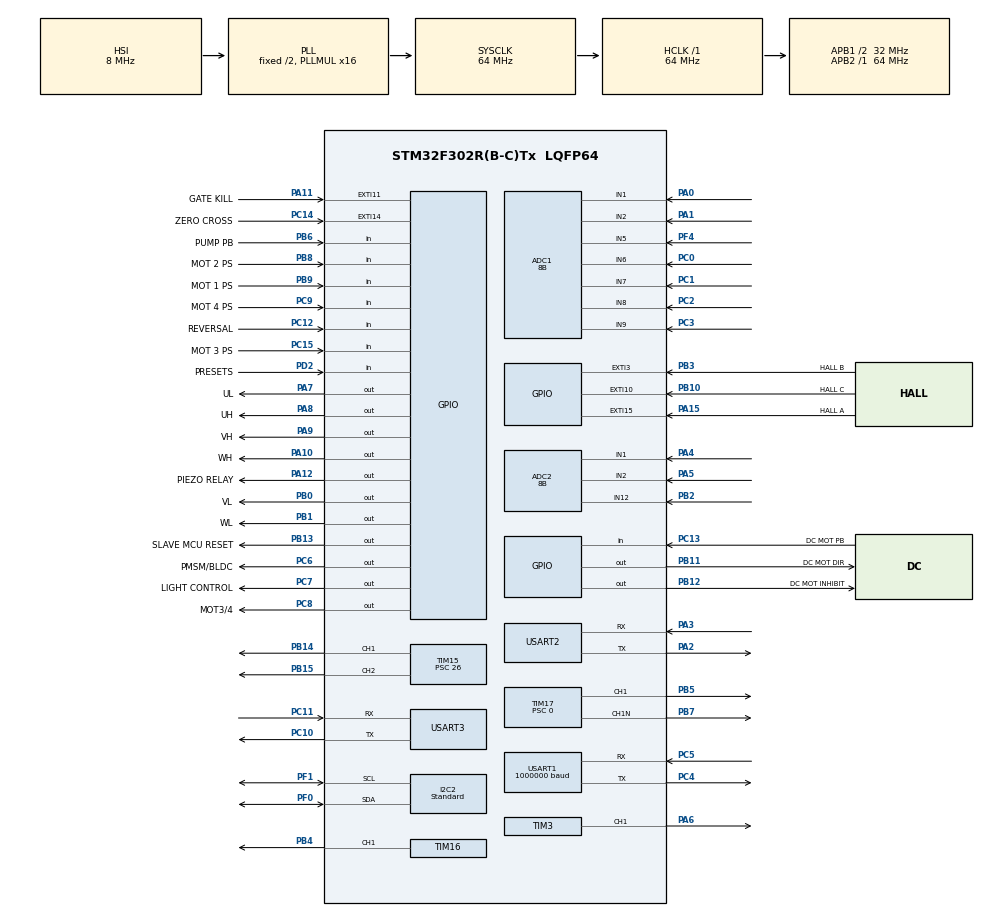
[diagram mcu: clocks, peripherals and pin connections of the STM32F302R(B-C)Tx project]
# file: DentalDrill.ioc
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ADC1.Channel-0\#ChannelRegularConversion=ADC_CHANNEL_1
ADC1.ClockPrescaler=ADC_CLOCK_ASYNC_DIV1
ADC1.ContinuousConvMode=DISABLE
ADC1.DMAContinuousRequests=DISABLE
ADC1.DataAlign=ADC_DATAALIGN_RIGHT
ADC1.DiscontinuousConvMode=DISABLE
ADC1.EOCSelection=ADC_EOC_SINGLE_CONV
ADC1.EnableAnalogWatchDog1=false
ADC1.EnableAnalogWatchDog2=false
ADC1.EnableAnalogWatchDog3=false
ADC1.EnableInjectedConversion=ENABLE
ADC1.EnableRegularConversion=ENABLE
ADC1.ExternalTrigConv=ADC_SOFTWARE_START
ADC1.ExternalTrigConvEdge=ADC_EXTERNALTRIGCONVEDGE_NONE
ADC1.InjNumberOfConversion=0
ADC1.LowPowerAutoWait=DISABLE
ADC1.NbrOfConversion=1
ADC1.NbrOfConversionFlag=1
ADC1.Offset-0\#ChannelRegularConversion=0
ADC1.OffsetNumber-0\#ChannelRegularConversion=ADC_OFFSET_NONE
ADC1.Overrun=ADC_OVR_DATA_OVERWRITTEN
ADC1.Rank-0\#ChannelRegularConversion=1
ADC1.Resolution=ADC_RESOLUTION_8B
ADC1.SamplingTime-0\#ChannelRegularConversion=ADC_SAMPLETIME_1CYCLE_5
ADC1.ScanConvMode=ADC_SCAN_DISABLE
ADC1.SubFamily=STM32F302xC
ADC1.master=1
ADC2.Channel-0\#ChannelRegularConversion=ADC_CHANNEL_12
ADC2.NbrOfConversionFlag=1
ADC2.Offset-0\#ChannelRegularConversion=0
ADC2.OffsetNumber-0\#ChannelRegularConversion=ADC_OFFSET_NONE
ADC2.Rank-0\#ChannelRegularConversion=1
ADC2.Resolution=ADC_RESOLUTION_8B
ADC2.SamplingTime-0\#ChannelRegularConversion=ADC_SAMPLETIME_1CYCLE_5
ADC2.SubFamily=STM32F302xC
I2C2.I2C_Speed_Mode=I2C_Standard
I2C2.Timing=0x10707DBC
Mcu.Family=STM32F3
Mcu.Name=STM32F302R(B-C)Tx
Mcu.Package=LQFP64
NVIC.EXTI15_10_IRQn=true\:5\:0\:true\:false\:true\:true
NVIC.EXTI3_IRQn=true\:5\:0\:true\:false\:true\:true
NVIC.PriorityGroup=NVIC_PRIORITYGROUP_4
NVIC.RCC_IRQn=true\:5\:0\:true\:false\:true\:true
NVIC.TIM1_UP_TIM16_IRQn=true\:5\:0\:true\:false\:true\:false
NVIC.TIM2_IRQn=true\:5\:0\:true\:false\:true\:true
NVIC.TIM4_IRQn=true\:5\:0\:true\:false\:true\:false
NVIC.TimeBase=TIM4_IRQn
NVIC.TimeBaseIP=TIM4
NVIC.USART1_IRQn=true\:5\:0\:true\:false\:true\:true
NVIC.USART2_IRQn=true\:5\:0\:true\:false\:true\:true
NVIC.USART3_IRQn=true\:5\:0\:true\:false\:true\:true
PA0.Mode=IN1-Single-Ended
PA0.Signal=ADC1_IN1
PA1.Mode=IN2-Single-Ended
PA1.Signal=ADC1_IN2
PA10.GPIO_Label=WH
PA10.GPIO_ModeDefaultOutputPP=GPIO_MODE_OUTPUT_PP
PA10.GPIO_PuPd=GPIO_PULLDOWN
PA10.PinState=GPIO_PIN_RESET
PA10.Signal=GPIO_Output
PA11.GPIO_Label=GATE KILL
PA11.GPIO_ModeDefaultEXTI=GPIO_MODE_IT_FALLING
PA11.GPIO_PuPd=GPIO_PULLUP
PA11.Signal=GPXTI11
PA12.GPIO_Label=PIEZO RELAY
PA12.GPIO_ModeDefaultOutputPP=GPIO_MODE_OUTPUT_PP
PA12.GPIO_PuPd=GPIO_PULLDOWN
PA12.PinState=GPIO_PIN_RESET
PA12.Signal=GPIO_Output
PA13.Mode=Serial_Wire
PA13.Signal=SYS_JTMS-SWDIO
PA14.Mode=Serial_Wire
PA14.Signal=SYS_JTCK-SWCLK
PA15.GPIO_Label=HALL A
PA15.GPIO_ModeDefaultEXTI=GPIO_MODE_IT_RISING_FALLING
PA15.GPIO_PuPd=GPIO_PULLUP
PA15.Signal=GPXTI15
PA2.Mode=Asynchronous
PA2.Signal=USART2_TX
PA3.Mode=Asynchronous
PA3.Signal=USART2_RX
PA4.Mode=IN1-Single-Ended
PA4.Signal=ADC2_IN1
PA5.Mode=IN2-Single-Ended
PA5.Signal=ADC2_IN2
PA6.Signal=S_TIM3_CH1
PA7.GPIO_Label=UL
PA7.GPIO_ModeDefaultOutputPP=GPIO_MODE_OUTPUT_PP
PA7.GPIO_PuPd=GPIO_PULLDOWN
PA7.PinState=GPIO_PIN_RESET
PA7.Signal=GPIO_Output
PA8.GPIO_Label=UH
PA8.GPIO_ModeDefaultOutputPP=GPIO_MODE_OUTPUT_PP
PA8.GPIO_PuPd=GPIO_PULLDOWN
PA8.PinState=GPIO_PIN_RESET
PA8.Signal=GPIO_Output
PA9.GPIO_Label=VH
PA9.GPIO_ModeDefaultOutputPP=GPIO_MODE_OUTPUT_PP
PA9.GPIO_PuPd=GPIO_PULLDOWN
PA9.PinState=GPIO_PIN_RESET
PA9.Signal=GPIO_Output
PB0.GPIO_Label=VL
PB0.GPIO_ModeDefaultOutputPP=GPIO_MODE_OUTPUT_PP
PB0.GPIO_PuPd=GPIO_PULLDOWN
PB0.PinState=GPIO_PIN_RESET
PB0.Signal=GPIO_Output
PB1.GPIO_Label=WL
PB1.GPIO_ModeDefaultOutputPP=GPIO_MODE_OUTPUT_PP
PB1.GPIO_PuPd=GPIO_PULLDOWN
PB1.PinState=GPIO_PIN_RESET
PB1.Signal=GPIO_Output
PB10.GPIO_Label=HALL C
PB10.GPIO_ModeDefaultEXTI=GPIO_MODE_IT_RISING_FALLING
PB10.GPIO_PuPd=GPIO_PULLUP
PB10.Signal=GPXTI10
PB11.GPIO_Label=DC MOT DIR
PB11.GPIO_ModeDefaultOutputPP=GPIO_MODE_OUTPUT_PP
PB11.GPIO_PuPd=GPIO_PULLDOWN
PB11.PinState=GPIO_PIN_RESET
PB11.Signal=GPIO_Output
PB12.GPIO_Label=DC MOT INHIBIT
PB12.GPIO_ModeDefaultOutputPP=GPIO_MODE_OUTPUT_OD
PB12.GPIO_PuPd=GPIO_PULLUP
PB12.PinState=GPIO_PIN_SET
PB12.Signal=GPIO_Output
PB13.GPIO_Label=SLAVE MCU RESET
PB13.GPIO_ModeDefaultOutputPP=GPIO_MODE_OUTPUT_PP
PB13.GPIO_PuPd=GPIO_PULLUP
PB13.PinState=GPIO_PIN_SET
PB13.Signal=GPIO_Output
PB14.Signal=S_TIM15_CH1
PB15.Signal=S_TIM15_CH2
PB2.Mode=IN12-Single-Ended
PB2.Signal=ADC2_IN12
PB3.GPIO_Label=HALL B
PB3.GPIO_ModeDefaultEXTI=GPIO_MODE_IT_RISING_FALLING
PB3.GPIO_PuPd=GPIO_PULLUP
PB3.Signal=GPXTI3
PB4.Signal=S_TIM16_CH1
PB5.Signal=S_TIM17_CH1
PB6.GPIO_Label=PUMP PB
PB6.GPIO_Mode=GPIO_MODE_INPUT
PB6.GPIO_PuPd=GPIO_PULLUP
PB6.Signal=GPIO_Input
PB7.Mode=PWM Generation1 CH1 CH1N
PB7.Signal=TIM17_CH1N
PB8.GPIO_Label=MOT 2 PS
PB8.GPIO_Mode=GPIO_MODE_INPUT
PB8.GPIO_PuPd=GPIO_PULLDOWN
PB8.Signal=GPIO_Input
PB9.GPIO_Label=MOT 1 PS
PB9.GPIO_Mode=GPIO_MODE_INPUT
PB9.GPIO_PuPd=GPIO_PULLDOWN
PB9.Signal=GPIO_Input
PC0.Signal=ADCx_IN6
PC1.Signal=ADCx_IN7
PC10.Mode=Asynchronous
PC10.Signal=USART3_TX
PC11.Mode=Asynchronous
PC11.Signal=USART3_RX
PC12.GPIO_Label=REVERSAL
PC12.GPIO_Mode=GPIO_MODE_INPUT
PC12.GPIO_PuPd=GPIO_PULLUP
PC12.Signal=GPIO_Input
PC13.GPIO_Label=DC MOT PB
PC13.GPIO_PuPd=GPIO_PULLUP
PC13.Signal=GPIO_Input
PC14-OSC32_IN.GPIO_Label=ZERO CROSS
PC14-OSC32_IN.GPIO_PuPd=GPIO_PULLUP
PC14-OSC32_IN.Signal=GPXTI14
PC15-OSC32_OUT.GPIO_Label=MOT 3 PS
PC15-OSC32_OUT.GPIO_PuPd=GPIO_PULLDOWN
PC15-OSC32_OUT.Signal=GPIO_Input
PC2.Signal=ADCx_IN8
PC3.Signal=ADCx_IN9
PC4.Mode=Asynchronous
PC4.Signal=USART1_TX
PC5.Mode=Asynchronous
PC5.Signal=USART1_RX
PC6.GPIO_Label=PMSM/BLDC
PC6.GPIO_ModeDefaultOutputPP=GPIO_MODE_OUTPUT_PP
PC6.GPIO_PuPd=GPIO_PULLDOWN
PC6.PinState=GPIO_PIN_RESET
PC6.Signal=GPIO_Output
PC7.GPIO_Label=LIGHT CONTROL
PC7.GPIO_PuPd=GPIO_PULLDOWN
PC7.Signal=GPIO_Output
PC8.GPIO_Label=MOT3/4
PC8.GPIO_ModeDefaultOutputPP=GPIO_MODE_OUTPUT_PP
PC8.GPIO_PuPd=GPIO_PULLDOWN
PC8.PinState=GPIO_PIN_RESET
PC8.Signal=GPIO_Output
PC9.GPIO_Label=MOT 4 PS
PC9.GPIO_Mode=GPIO_MODE_INPUT
PC9.GPIO_PuPd=GPIO_PULLDOWN
PC9.Signal=GPIO_Input
PD2.GPIO_Label=PRESETS
PD2.GPIO_Mode=GPIO_MODE_INPUT
PD2.GPIO_PuPd=GPIO_PULLUP
PD2.Signal=GPIO_Input
PF0-OSC_IN.Mode=I2C
PF0-OSC_IN.Signal=I2C2_SDA
PF1-OSC_OUT.Mode=I2C
PF1-OSC_OUT.Signal=I2C2_SCL
PF4.Mode=IN5-Single-Ended
PF4.Signal=ADC1_IN5
ProjectManager.HeapSize=0x200
ProjectManager.StackSize=0x400
ProjectManager.TargetToolchain=Makefile
RCC.AHBFreq_Value=64000000
RCC.APB1CLKDivider=RCC_HCLK_DIV2
RCC.APB1Freq_Value=32000000
RCC.APB1TimFreq_Value=64000000
RCC.APB2Freq_Value=64000000
RCC.APB2TimFreq_Value=64000000
RCC.CortexFreq_Value=64000000
RCC.HCLKFreq_Value=64000000
RCC.HSE_VALUE=8000000
RCC.HSI_VALUE=8000000
RCC.I2c2ClockSelection=RCC_I2C2CLKSOURCE_SYSCLK
RCC.LSE_VALUE=32768
RCC.PLLMUL=RCC_PLL_MUL16
RCC.SYSCLKFreq_VALUE=64000000
RCC.SYSCLKSourceVirtual=RCC_SYSCLKSOURCE_PLLCLK
RCC.USBFreq_Value=64000000
SH.ADCx_IN6.0=ADC1_IN6,IN6-Single-Ended
SH.ADCx_IN7.0=ADC1_IN7,IN7-Single-Ended
SH.ADCx_IN8.0=ADC1_IN8,IN8-Single-Ended
SH.ADCx_IN9.0=ADC1_IN9,IN9-Single-Ended
SH.S_TIM15_CH1.0=TIM15_CH1,PWM Generation1 CH1
SH.S_TIM15_CH2.0=TIM15_CH2,PWM Generation2 CH2
SH.S_TIM16_CH1.0=TIM16_CH1,PWM Generation1 CH1
SH.S_TIM17_CH1.0=TIM17_CH1,PWM Generation1 CH1 CH1N
SH.S_TIM3_CH1.0=TIM3_CH1,PWM Generation1 CH1
TIM15.Channel-PWM\ Generation1\ CH1=TIM_CHANNEL_1
TIM15.Channel-PWM\ Generation2\ CH2=TIM_CHANNEL_2
TIM15.Period=99
TIM15.Prescaler=26
TIM15.Pulse-PWM\ Generation1\ CH1=50
TIM15.Pulse-PWM\ Generation2\ CH2=50
TIM16.Channel=TIM_CHANNEL_1
TIM16.Period=99
TIM16.Prescaler=26
TIM16.Pulse=50
TIM17.Channel=TIM_CHANNEL_1
TIM17.DeadTime=18
TIM17.Period=639
TIM17.Prescaler=0
TIM17.Pulse=360
TIM2.AutoReloadPreload=TIM_AUTORELOAD_PRELOAD_DISABLE
TIM2.ClockDivision=TIM_CLOCKDIVISION_DIV1
TIM2.Period=0xFFFFFFFF
TIM2.Prescaler=63
TIM2.TIM_MasterOutputTrigger=TIM_TRGO_RESET
TIM3.Channel-PWM\ Generation1\ CH1=TIM_CHANNEL_1
TIM3.Period=99
TIM3.Prescaler=639
TIM3.Pulse-PWM\ Generation1\ CH1=50
USART1.BaudRate=1000000
USART1.VirtualMode-Asynchronous=VM_ASYNC
USART2.VirtualMode-Asynchronous=VM_ASYNC
USART3.VirtualMode-Asynchronous=VM_ASYNC
VP_SYS_VS_tim4.Mode=TIM4
VP_TIM15_VS_ClockSourceINT.Mode=Internal
VP_TIM16_VS_ClockSourceINT.Mode=Enable_Timer
VP_TIM17_VS_ClockSourceINT.Mode=Enable_Timer
VP_TIM2_VS_ClockSourceINT.Mode=Internal
VP_TIM3_VS_ClockSourceINT.Mode=Internal
board=DentalDrill

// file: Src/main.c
/**
  ******************************************************************************
  * @file           : main.c
  * @brief          : Main program body
  ******************************************************************************
  ** This notice applies to any and all portions of this file
  * that are not between comment pairs USER CODE BEGIN and
  * USER CODE END. Other portions of this file, whether
  * inserted by the user or by software development tools
  * are owned by their respective copyright owners.
  *
  * COPYRIGHT(c) 2018 STMicroelectronics
  *
  * Redistribution and use in source and binary forms, with or without modification,
  * are permitted provided that the following conditions are met:
  *   1. Redistributions of source code must retain the above copyright notice,
  *      this list of conditions and the following disclaimer.
  *   2. Redistributions in binary form must reproduce the above copyright notice,
  *      this list of conditions and the following disclaimer in the documentation
  *      and/or other materials provided with the distribution.
  *   3. Neither the name of STMicroelectronics nor the names of its contributors
  *      may be used to endorse or promote products derived from this software
  *      without specific prior written permission.
  *
  * THIS SOFTWARE IS PROVIDED BY THE COPYRIGHT HOLDERS AND CONTRIBUTORS "AS IS"
  * AND ANY EXPRESS OR IMPLIED WARRANTIES, INCLUDING, BUT NOT LIMITED TO, THE
  * IMPLIED WARRANTIES OF MERCHANTABILITY AND FITNESS FOR A PARTICULAR PURPOSE ARE
  * DISCLAIMED. IN NO EVENT SHALL THE COPYRIGHT HOLDER OR CONTRIBUTORS BE LIABLE
  * FOR ANY DIRECT, INDIRECT, INCIDENTAL, SPECIAL, EXEMPLARY, OR CONSEQUENTIAL
  * DAMAGES (INCLUDING, BUT NOT LIMITED TO, PROCUREMENT OF SUBSTITUTE GOODS OR
  * SERVICES; LOSS OF USE, DATA, OR PROFITS; OR BUSINESS INTERRUPTION) HOWEVER
  * CAUSED AND ON ANY THEORY OF LIABILITY, WHETHER IN CONTRACT, STRICT LIABILITY,
  * OR TORT (INCLUDING NEGLIGENCE OR OTHERWISE) ARISING IN ANY WAY OUT OF THE USE
  * OF THIS SOFTWARE, EVEN IF ADVISED OF THE POSSIBILITY OF SUCH DAMAGE.
  *
  ******************************************************************************
  */
#include "main.h"
#include "stm32f3xx_hal.h"
#include "adc.h"
#include "i2c.h"
#include "tim.h"
#include "usart.h"
#include "gpio.h"

/* USER CODE BEGIN PV */
/* Private variables ---------------------------------------------------------*/

/* USER CODE END PV */

void SystemClock_Config(void);

/* USER CODE BEGIN PFP */
/* Private function prototypes -----------------------------------------------*/

/* USER CODE END PFP */

/* USER CODE BEGIN 0 */
//This is a somewhat dirty hack to remove the STM main function from the build while not affecting
//generated HAL code, aside from what is included in the main function. Driver initialization is now
//the responsibility of the application and jel (i.e. the MX_GPIO_Init(), MX_..._Init() functions).
//The HAL_Init() and SystemClock_Config() functions are handled by the jel on bootup, and the core
//timer, UART and GPIO are also initialized on startup.
__attribute__((unused)) static void DUMMY(void)
{
#ifdef false
/* USER CODE END 0 */

int main(void)
{

  /* MCU Configuration----------------------------------------------------------*/

  /* Reset of all peripherals, Initializes the Flash interface and the Systick. */
  HAL_Init();

  /* Configure the system clock */
  SystemClock_Config();

  /* Initialize all configured peripherals */
  MX_GPIO_Init();
  MX_USART2_UART_Init();
  MX_USART1_UART_Init();
  MX_TIM17_Init();
  MX_TIM16_Init();
  MX_TIM3_Init();
  MX_TIM15_Init();
  MX_ADC1_Init();
  MX_ADC2_Init();
  MX_I2C2_Init();
  MX_USART3_UART_Init();
  MX_TIM2_Init();

  /* Infinite loop */
  while (1)
  {

  /* USER CODE BEGIN 3 */

  }
#endif
  /* USER CODE END 3 */

}

void SystemClock_Config(void)
{

  RCC_OscInitTypeDef RCC_OscInitStruct;
  RCC_ClkInitTypeDef RCC_ClkInitStruct;
  RCC_PeriphCLKInitTypeDef PeriphClkInit;

    /**Initializes the CPU, AHB and APB busses clocks
    */
  RCC_OscInitStruct.OscillatorType = RCC_OSCILLATORTYPE_HSI;
  RCC_OscInitStruct.HSIState = RCC_HSI_ON;
  RCC_OscInitStruct.HSICalibrationValue = 16;
  RCC_OscInitStruct.PLL.PLLState = RCC_PLL_ON;
  RCC_OscInitStruct.PLL.PLLSource = RCC_PLLSOURCE_HSI;
  RCC_OscInitStruct.PLL.PLLMUL = RCC_PLL_MUL16;
  if (HAL_RCC_OscConfig(&RCC_OscInitStruct) != HAL_OK)
  {
    _Error_Handler(__FILE__, __LINE__);
  }

    /**Initializes the CPU, AHB and APB busses clocks
    */
  RCC_ClkInitStruct.ClockType = RCC_CLOCKTYPE_HCLK|RCC_CLOCKTYPE_SYSCLK
                              |RCC_CLOCKTYPE_PCLK1|RCC_CLOCKTYPE_PCLK2;
  RCC_ClkInitStruct.SYSCLKSource = RCC_SYSCLKSOURCE_PLLCLK;
  RCC_ClkInitStruct.AHBCLKDivider = RCC_SYSCLK_DIV1;
  RCC_ClkInitStruct.APB1CLKDivider = RCC_HCLK_DIV2;
  RCC_ClkInitStruct.APB2CLKDivider = RCC_HCLK_DIV1;

  if (HAL_RCC_ClockConfig(&RCC_ClkInitStruct, FLASH_LATENCY_2) != HAL_OK)
  {
    _Error_Handler(__FILE__, __LINE__);
  }

  PeriphClkInit.PeriphClockSelection = RCC_PERIPHCLK_USART1|RCC_PERIPHCLK_USART2
                              |RCC_PERIPHCLK_USART3|RCC_PERIPHCLK_I2C2
                              |RCC_PERIPHCLK_ADC12;
  PeriphClkInit.Usart1ClockSelection = RCC_USART1CLKSOURCE_PCLK2;
  PeriphClkInit.Usart2ClockSelection = RCC_USART2CLKSOURCE_PCLK1;
  PeriphClkInit.Usart3ClockSelection = RCC_USART3CLKSOURCE_PCLK1;
  PeriphClkInit.Adc12ClockSelection = RCC_ADC12PLLCLK_DIV1;
  PeriphClkInit.I2c2ClockSelection = RCC_I2C2CLKSOURCE_SYSCLK;
  if (HAL_RCCEx_PeriphCLKConfig(&PeriphClkInit) != HAL_OK)
  {
    _Error_Handler(__FILE__, __LINE__);
  }

    /**Configure the Systick interrupt time
    */
  HAL_SYSTICK_Config(HAL_RCC_GetHCLKFreq()/1000);

    /**Configure the Systick
    */
  HAL_SYSTICK_CLKSourceConfig(SYSTICK_CLKSOURCE_HCLK);

  /* SysTick_IRQn interrupt configuration */
  HAL_NVIC_SetPriority(SysTick_IRQn, 15, 0);
}

/* USER CODE BEGIN 4 */
extern void jel_hw_sysclock_isr(void);

/* USER CODE END 4 */

void HAL_TIM_PeriodElapsedCallback(TIM_HandleTypeDef *htim)
{
  if (htim->Instance == TIM4) {
    HAL_IncTick();
  }
  /* USER CODE BEGIN Callback 1 */
  if(htim->Instance == TIM2)
  {
    jel_hw_sysclock_isr();
  }
  /* USER CODE END Callback 1 */
}

void _Error_Handler(char *file, int line)
{
  while(1)
  {
  }
}

/************************ (C) COPYRIGHT STMicroelectronics *****END OF FILE****/
